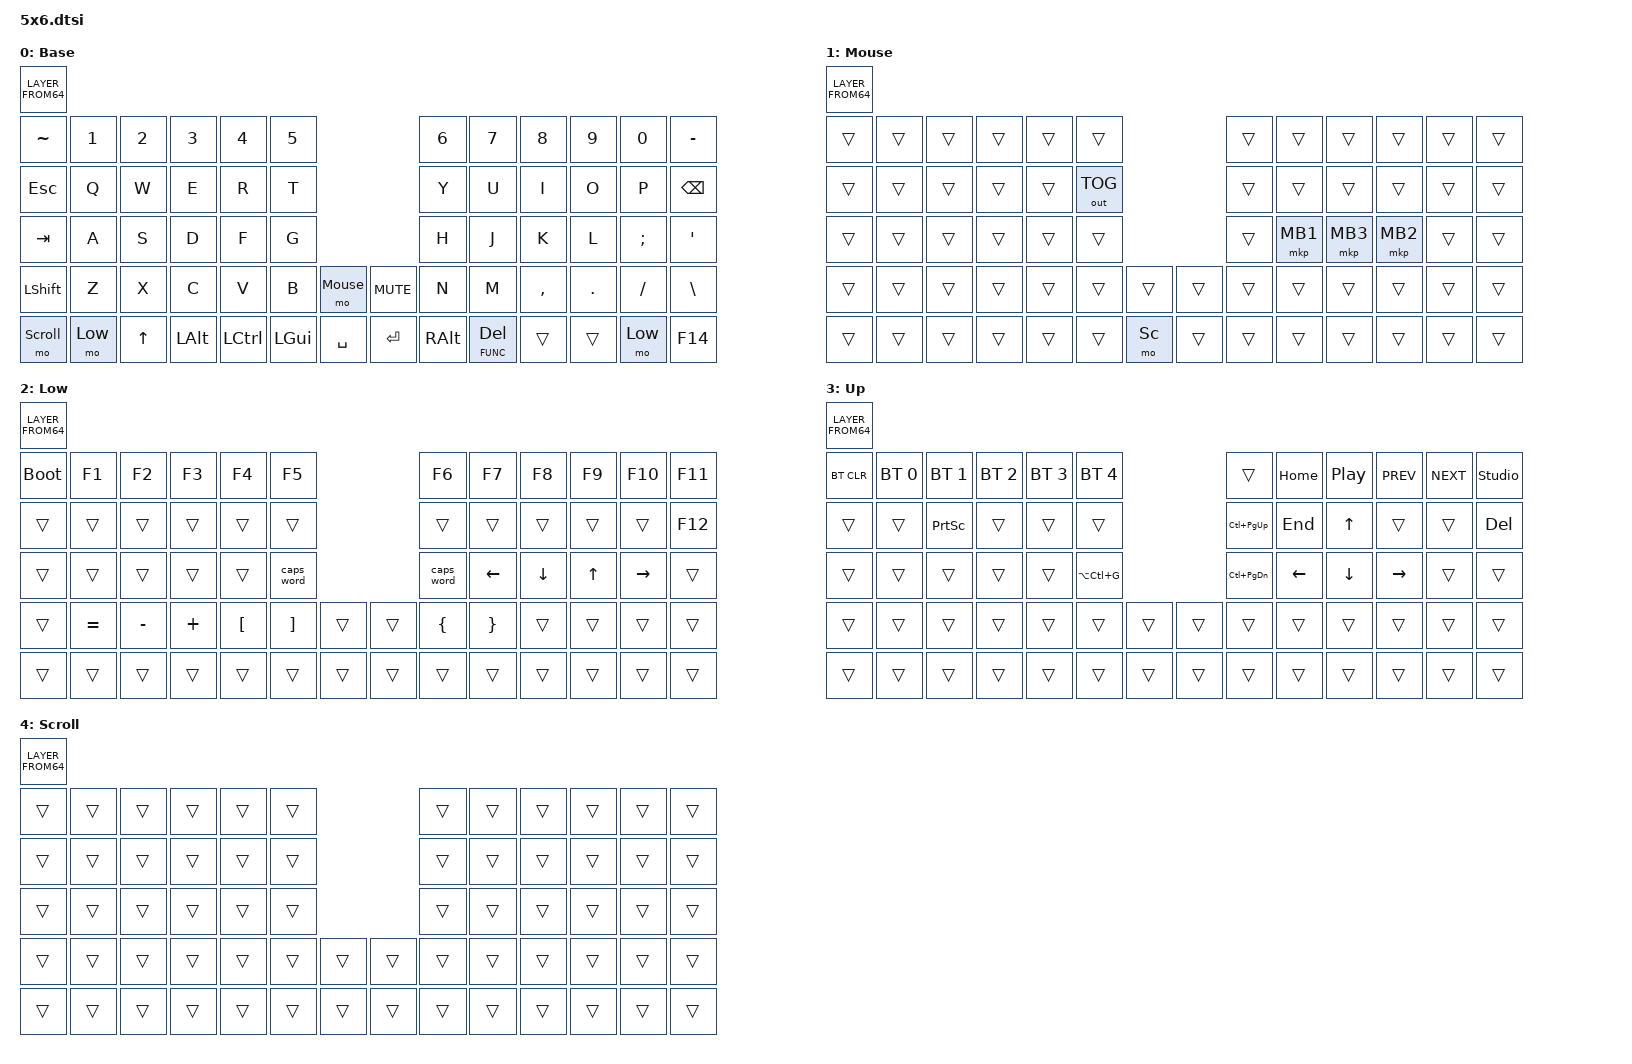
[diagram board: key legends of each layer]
// ZMK includes
#include <behaviors.dtsi>
#include <dt-bindings/zmk/bt.h>
#include <dt-bindings/zmk/ext_power.h>
#include <dt-bindings/zmk/keys.h>
#include <dt-bindings/zmk/pointing.h>
#include <dt-bindings/zmk/outputs.h>

#define ___ &trans
#define BASE 0
#define Mouse 1
#define Low 2
#define Up 3
#define Scroll 4

#include "combos.dtsi"

/ {
    behaviors {
        hrm: hrm {
            label = "hrm";
            compatible = "zmk,behavior-hold-tap";
            #binding-cells = <2>;
            flavor = "balanced";
            tapping-term-ms = <280>;
            quick-tap-ms = <125>;
            global-quick-tap;
            bindings = <&kp>, <&kp>;
        };
    };

    sensors { triggers-per-rotation = <20>; };
};

/ {
    keymap {
        compatible = "zmk,keymap";

        default_layer {
            label = "Base";
            bindings = < LAYER_FROM64( \
&kp TILDE,     &kp N1,        &kp N2,        &kp N3,        &kp N4,        &kp N5,                                  &kp N6,     &kp N7,        &kp N8,     &kp N9,     &kp N0,     &kp MINUS,
&kp ESCAPE,    &kp Q,         &kp W,         &kp E,         &kp R,         &kp T,                                   &kp Y,      &kp U,         &kp I,      &kp O,      &kp P,      &kp BSPC,
&kp TAB,       &kp A,         &kp S,         &kp D,         &kp F,         &kp G,                                   &kp H,      &kp J,         &kp K,      &kp L,      &kp SEMI,   &kp SQT,
&kp LSHFT,     &kp Z,         &kp X,         &kp C,         &kp V,         &kp B,      &mo Mouse,   &kp C_MUTE,   &kp N,      &kp M,         &kp COMMA,  &kp DOT,    &kp FSLH,   &kp BSLH,
&mo Scroll,    &mo Low,       &kp UP,        &kp LALT,      &kp LCTRL,     &kp LGUI,   &kp SPACE,   &kp ENTER,    &kp RALT,   &lt FUNC DEL,  &trans,     &trans,     &mo Low,    &kp F14
            )>;

            // sensor-bindings = <&inc_dec_kp C_VOLUME_UP C_VOL_DN &inc_dec_kp LC(Y) LC(Z)>;
        };

        mouse {
            label = "Mouse";
            bindings = < LAYER_FROM64( \
&trans,    &trans,  &trans,   &trans,   &trans,   &trans,                    &trans,  &trans,   &trans,   &trans,   &trans,   &trans,
&trans,    &trans,  &trans,   &trans,   &trans,   &out OUT_TOG,              &trans,  &trans,   &trans,   &trans,   &trans,   &trans,
&trans,    &trans,  &trans,   &trans,   &trans,   &trans,                    &trans,  &mkp MB1, &mkp MB3, &mkp MB2,   &trans,   &trans,
&trans,    &trans,  &trans,   &trans,   &trans,   &trans,  &trans,  &trans,  &trans,  &trans,   &trans,   &trans,   &trans,   &trans,
&trans,    &trans,  &trans,   &trans,   &trans,   &trans,  &mo Sc,  &trans,  &trans,  &trans,   &trans,   &trans,   &trans,   &trans
            )>;
        };

        low {
            label = "Low";
            bindings = < LAYER_FROM64( \
&bootloader,   &kp F1,        &kp F2,        &kp F3,        &kp F4,        &kp F5,                          &kp F6,        &kp F7,     &kp F8,     &kp F9,     &kp F10,     &kp F11,
&trans,        &trans,        &trans,        &trans,        &trans,        &trans,                          &trans,        &trans,     &trans,     &trans,     &trans,      &kp F12,
&trans,        &trans,        &trans,        &trans,        &trans,        &caps_word,                      &caps_word,    &kp LEFT,   &kp DOWN,   &kp UP,     &kp RIGHT,   &trans,
&trans,        &kp EQUAL,     &kp MINUS,     &kp PLUS,      &kp LBKT,      &kp RBKT,   &trans,   &trans,    &kp LBRC,      &kp RBRC,   &trans,     &trans,     &trans,      &trans,
&trans,        &trans,        &trans,        &trans,        &trans,        &trans,     &trans,   &trans,    &trans,        &trans,     &trans,     &trans,     &trans,      &trans
            )>;
        };

        up {
            label = "Up";
            bindings = < LAYER_FROM64( \
&bt BT_CLR,    &bt BT_SEL 0,   &bt BT_SEL 1,   &bt BT_SEL 2,   &bt BT_SEL 3,   &bt BT_SEL 4,                   &trans,           &kp HOME,        &kp C_PP,      &kp C_PREV,   &kp C_NEXT,   &studio_unlock,
&trans,        &trans,         &kp PSCRN,      &trans,         &trans,         &trans,                         &kp LC(PG_UP),    &kp END,         &kp UP,        &trans,       &trans,       &kp DEL,
&trans,        &trans,         &trans,         &trans,         &trans,         &kp LA(LC(G)),                  &kp LC(PG_DN),    &kp LEFT,        &kp DOWN,      &kp RIGHT,    &trans,       &trans,
&trans,        &trans,         &trans,         &trans,         &trans,         &trans,      &trans,  &trans,  &trans,           &trans,          &trans,        &trans,       &trans,       &trans,
&trans,        &trans,         &trans,         &trans,         &trans,         &trans,      &trans,  &trans,  &trans,           &trans,          &trans,        &trans,       &trans,       &trans
            )>;
        };

        scroll {
            label = "Scroll";
            bindings = < LAYER_FROM64( \
&trans,  &trans,  &trans,  &trans,  &trans,  &trans,                    &trans,  &trans,  &trans,  &trans,  &trans,  &trans,
&trans,  &trans,  &trans,  &trans,  &trans,  &trans,                    &trans,  &trans,  &trans,  &trans,  &trans,  &trans,
&trans,  &trans,  &trans,  &trans,  &trans,  &trans,                    &trans,  &trans,  &trans,  &trans,  &trans,  &trans,
&trans,  &trans,  &trans,  &trans,  &trans,  &trans,  &trans,  &trans,  &trans,  &trans,  &trans,  &trans,  &trans,  &trans,
&trans,  &trans,  &trans,  &trans,  &trans,  &trans,  &trans,  &trans,  &trans,  &trans,  &trans,  &trans,  &trans,  &trans
            )>;
        };

        
    };
};
